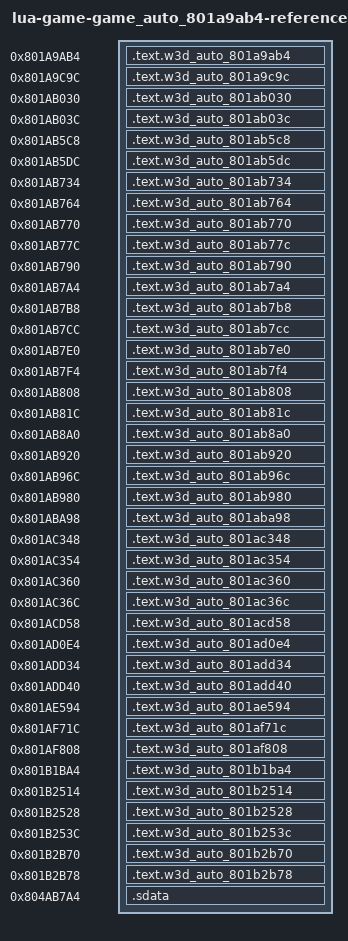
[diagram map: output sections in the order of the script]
/* Generated reference-only placements. All bodies are source-built. */
OUTPUT_FORMAT("elf32-powerpc")
OUTPUT_ARCH(powerpc)
ENTRY(w3d_auto_801a9ab4)
_SDA_BASE_ = 0x804b2540;
_SDA2_BASE_ = 0x804c2540;
fn_801AB05C = 0x801ab05c;
fn_802EEDC0 = 0x802eedc0;
SECTIONS {
  .text.w3d_auto_801a9ab4 0x801a9ab4 : { *(.text.w3d_auto_801a9ab4) }
  .text.w3d_auto_801a9c9c 0x801a9c9c : { *(.text.w3d_auto_801a9c9c) }
  .text.w3d_auto_801ab030 0x801ab030 : { *(.text.w3d_auto_801ab030) }
  .text.w3d_auto_801ab03c 0x801ab03c : { *(.text.w3d_auto_801ab03c) }
  .text.w3d_auto_801ab5c8 0x801ab5c8 : { *(.text.w3d_auto_801ab5c8) }
  .text.w3d_auto_801ab5dc 0x801ab5dc : { *(.text.w3d_auto_801ab5dc) }
  .text.w3d_auto_801ab734 0x801ab734 : { *(.text.w3d_auto_801ab734) }
  .text.w3d_auto_801ab764 0x801ab764 : { *(.text.w3d_auto_801ab764) }
  .text.w3d_auto_801ab770 0x801ab770 : { *(.text.w3d_auto_801ab770) }
  .text.w3d_auto_801ab77c 0x801ab77c : { *(.text.w3d_auto_801ab77c) }
  .text.w3d_auto_801ab790 0x801ab790 : { *(.text.w3d_auto_801ab790) }
  .text.w3d_auto_801ab7a4 0x801ab7a4 : { *(.text.w3d_auto_801ab7a4) }
  .text.w3d_auto_801ab7b8 0x801ab7b8 : { *(.text.w3d_auto_801ab7b8) }
  .text.w3d_auto_801ab7cc 0x801ab7cc : { *(.text.w3d_auto_801ab7cc) }
  .text.w3d_auto_801ab7e0 0x801ab7e0 : { *(.text.w3d_auto_801ab7e0) }
  .text.w3d_auto_801ab7f4 0x801ab7f4 : { *(.text.w3d_auto_801ab7f4) }
  .text.w3d_auto_801ab808 0x801ab808 : { *(.text.w3d_auto_801ab808) }
  .text.w3d_auto_801ab81c 0x801ab81c : { *(.text.w3d_auto_801ab81c) }
  .text.w3d_auto_801ab8a0 0x801ab8a0 : { *(.text.w3d_auto_801ab8a0) }
  .text.w3d_auto_801ab920 0x801ab920 : { *(.text.w3d_auto_801ab920) }
  .text.w3d_auto_801ab96c 0x801ab96c : { *(.text.w3d_auto_801ab96c) }
  .text.w3d_auto_801ab980 0x801ab980 : { *(.text.w3d_auto_801ab980) }
  .text.w3d_auto_801aba98 0x801aba98 : { *(.text.w3d_auto_801aba98) }
  .text.w3d_auto_801ac348 0x801ac348 : { *(.text.w3d_auto_801ac348) }
  .text.w3d_auto_801ac354 0x801ac354 : { *(.text.w3d_auto_801ac354) }
  .text.w3d_auto_801ac360 0x801ac360 : { *(.text.w3d_auto_801ac360) }
  .text.w3d_auto_801ac36c 0x801ac36c : { *(.text.w3d_auto_801ac36c) }
  .text.w3d_auto_801acd58 0x801acd58 : { *(.text.w3d_auto_801acd58) }
  .text.w3d_auto_801ad0e4 0x801ad0e4 : { *(.text.w3d_auto_801ad0e4) }
  .text.w3d_auto_801add34 0x801add34 : { *(.text.w3d_auto_801add34) }
  .text.w3d_auto_801add40 0x801add40 : { *(.text.w3d_auto_801add40) }
  .text.w3d_auto_801ae594 0x801ae594 : { *(.text.w3d_auto_801ae594) }
  .text.w3d_auto_801af71c 0x801af71c : { *(.text.w3d_auto_801af71c) }
  .text.w3d_auto_801af808 0x801af808 : { *(.text.w3d_auto_801af808) }
  .text.w3d_auto_801b1ba4 0x801b1ba4 : { *(.text.w3d_auto_801b1ba4) }
  .text.w3d_auto_801b2514 0x801b2514 : { *(.text.w3d_auto_801b2514) }
  .text.w3d_auto_801b2528 0x801b2528 : { *(.text.w3d_auto_801b2528) }
  .text.w3d_auto_801b253c 0x801b253c : { *(.text.w3d_auto_801b253c) }
  .text.w3d_auto_801b2b70 0x801b2b70 : { *(.text.w3d_auto_801b2b70) }
  .text.w3d_auto_801b2b78 0x801b2b78 : { *(.text.w3d_auto_801b2b78) }
  .sdata 0x804ab7a4 (NOLOAD) : {
    . = 0x0; lbl_804AB7A4 = .;
    . += 1; }
  /DISCARD/ : { *(.text*) *(.rodata*) *(.data*) *(.bss*) *(.sdata*) *(.sbss*) *(.comment) }
}
